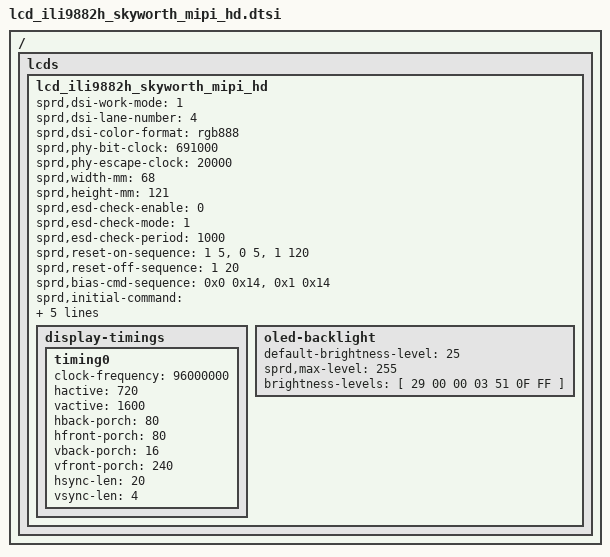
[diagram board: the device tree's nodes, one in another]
/ { lcds {
	lcd_ili9882h_skyworth_mipi_hd: lcd_ili9882h_skyworth_mipi_hd {

		sprd,dsi-work-mode = <1>;
		sprd,dsi-lane-number = <4>;
		sprd,dsi-color-format = "rgb888";

		sprd,phy-bit-clock = <691000>;
		sprd,phy-escape-clock = <20000>;

		sprd,width-mm = <68>;
		sprd,height-mm = <121>;

		sprd,esd-check-enable = <0>;
		sprd,esd-check-mode = <1>;
		sprd,esd-check-period = <1000>;

		sprd,reset-on-sequence = <1 5>, <0 5>, <1 120>;
		sprd,reset-off-sequence = <1 20>;
		sprd,bias-cmd-sequence =  <0x0 0x14>, <0x1 0x14>;

		sprd,initial-command = [
			39 00 00 04 FF 98 82 01
			23 00 00 02 00 41  //42 STV A rise    20201022
			23 00 00 02 01 32  //33 STV A overlap 20201022
			23 00 00 02 02 01
			23 00 00 02 03 00
			23 00 00 02 04 03  //02 STV B rise    20201022
			23 00 00 02 05 30  //31 STV B overlap 20201022
			23 00 00 02 07 00
			23 00 00 02 08 01  //80 CLK A rise    20201022    
			23 00 00 02 09 80  //81 CLK A fall    20201022 
			23 00 00 02 0a 70  //71 CLK A overlap 20201022
			23 00 00 02 0b 00
			23 00 00 02 0c 0E  //01               20201022
			23 00 00 02 0d 0E  //01               20201022
			23 00 00 02 0e 00
			23 00 00 02 0f 00
			23 00 00 02 28 88 //83 STCH1 RISE     20201022
			23 00 00 02 29 88 //STCH1 FALL     
			23 00 00 02 2a 00
			23 00 00 02 2b 00
			23 00 00 02 31 07
			23 00 00 02 32 0c
			23 00 00 02 33 22
			23 00 00 02 34 23 //GOUT_4R_FW
			23 00 00 02 35 07
			23 00 00 02 36 08
			23 00 00 02 37 16
			23 00 00 02 38 14
			23 00 00 02 39 12
			23 00 00 02 3a 10
			23 00 00 02 3b 21
			23 00 00 02 3c 07 //GOUT_12R_FW
			23 00 00 02 3d 07
			23 00 00 02 3e 07
			23 00 00 02 3f 07
			23 00 00 02 40 07
			23 00 00 02 41 07
			23 00 00 02 42 07
			23 00 00 02 43 07
			23 00 00 02 44 07
			23 00 00 02 45 07
			23 00 00 02 46 07                                      
			23 00 00 02 47 07
			23 00 00 02 48 0d
			23 00 00 02 49 22
			23 00 00 02 4a 23 //GOUT_4L_FW
			23 00 00 02 4b 07
			23 00 00 02 4c 09
			23 00 00 02 4d 17
			23 00 00 02 4e 15
			23 00 00 02 4f 13
			23 00 00 02 50 11
			23 00 00 02 51 21
			23 00 00 02 52 07 //GOUT_12L_FW
			23 00 00 02 53 07
			23 00 00 02 54 07
			23 00 00 02 55 07
			23 00 00 02 56 07
			23 00 00 02 57 07
			23 00 00 02 58 07
			23 00 00 02 59 07
			23 00 00 02 5a 07
			23 00 00 02 5b 07
			23 00 00 02 5c 07

			23 00 00 02 61 07
			23 00 00 02 62 0d
			23 00 00 02 63 22
			23 00 00 02 64 23 //GOUT_4R_BW
			23 00 00 02 65 07
			23 00 00 02 66 09
			23 00 00 02 67 11
			23 00 00 02 68 13
			23 00 00 02 69 15
			23 00 00 02 6a 17
			23 00 00 02 6b 21
			23 00 00 02 6c 07 //GOUT_12R_BW
			23 00 00 02 6d 07
			23 00 00 02 6e 07
			23 00 00 02 6f 07
			23 00 00 02 70 07
			23 00 00 02 71 07
			23 00 00 02 72 07
			23 00 00 02 73 07
			23 00 00 02 74 07
			23 00 00 02 75 07
			23 00 00 02 76 07                                        
			23 00 00 02 77 07
			23 00 00 02 78 0c
			23 00 00 02 79 22
			23 00 00 02 7a 23 //GOUT_4L_BW
			23 00 00 02 7b 07
			23 00 00 02 7c 08
			23 00 00 02 7d 10
			23 00 00 02 7e 12
			23 00 00 02 7f 14
			23 00 00 02 80 16
			23 00 00 02 81 21
			23 00 00 02 82 07 //GOUT_12L_BW
			23 00 00 02 83 07
			23 00 00 02 84 07
			23 00 00 02 85 07
			23 00 00 02 86 07
			23 00 00 02 87 07
			23 00 00 02 88 07
			23 00 00 02 89 07
			23 00 00 02 8a 07
			23 00 00 02 8b 07
			23 00 00 02 8c 07
			23 00 00 02 a0 01
			23 00 00 02 a7 00  //LVRA CLK RISE CLW
			23 00 00 02 a8 00  //LVRA CLK RISE CLW
			23 00 00 02 b0 33
			23 00 00 02 ba 06
			23 00 00 02 c0 07
			23 00 00 02 c1 00
			23 00 00 02 c2 00
			23 00 00 02 c3 00
			23 00 00 02 c4 00
			23 00 00 02 ca 44                                
			23 00 00 02 d0 01
			23 00 00 02 d1 22
			23 00 00 02 d3 40
			23 00 00 02 d5 51
			23 00 00 02 d6 20
			23 00 00 02 d7 01
			23 00 00 02 d8 00
			23 00 00 02 dc c2
			23 00 00 02 dd 10
			23 00 00 02 df b6
			23 00 00 02 e0 3E
			23 00 00 02 e2 47 //SRC power off GND
			23 00 00 02 e7 54                                       
			23 00 00 02 e6 22
			23 00 00 02 ee 15
			23 00 00 02 f1 00
			23 00 00 02 f2 00
			23 00 00 02 fa df

			// RTN. Internal VBP, Internal VFP
			39 00 00 04 FF 98 82 02
			23 00 00 02 06 9F     // Internal Line Time (RTN)  9C  20200813
			23 00 00 02 0B A0     // Internal VFP[9]
			23 00 00 02 0C 00     // Internal VFP[8]
			23 00 00 02 0D 1C     // Internal VBP
			23 00 00 02 0E 43     // Internal VFP
			23 00 00 02 F1 1C     // Tcon ESD option
			23 00 00 02 4B 5A     // line_chopper
			23 00 00 02 50 CA     // line_chopper
			23 00 00 02 51 50     // line_chopper
			23 00 00 02 40 4B     // Data_in=7us
			23 00 00 02 4D CE     // Power Saving Off
			23 00 00 02 73 04     // notch tuning
			23 00 00 02 70 32     // notch tuning   
			39 00 00 04 FF 98 82 03
			23 00 00 02 85 40	//DIVIDUAL
			23 00 00 02 87 4D	//01
			23 00 00 02 88 C5
			23 00 00 02 89 E5
			23 00 00 02 8A EF
			23 00 00 02 8B FF
			23 00 00 02 8C D2	//02
			23 00 00 02 8D D6
			23 00 00 02 8E DA
			23 00 00 02 8F DE
			23 00 00 02 90 DF
			23 00 00 02 91 E6
			23 00 00 02 92 E9
			23 00 00 02 93 ED
			23 00 00 02 94 F0
			23 00 00 02 95 FF
			23 00 00 02 96 B5	//03
			23 00 00 02 97 BA
			23 00 00 02 98 BF
			23 00 00 02 99 C3
			23 00 00 02 9A C9
			23 00 00 02 9B CD		
			23 00 00 02 9C D9
			23 00 00 02 9D E6
			23 00 00 02 9E F6		
			23 00 00 02 9F FB


			// Power Setting
			39 00 00 04 FF 98 82 05
			23 00 00 02 A8 62
			23 00 00 02 63 73     // GVDDN = -4.8V
			23 00 00 02 64 73     // GVDDP = 4.8V
			23 00 00 02 68 65     // VGHO = 12V
			23 00 00 02 69 6B     // VGH = 13V
			23 00 00 02 6A A1     // VGLO = -12V
			23 00 00 02 6B 93     // VGL = -13V
			23 00 00 02 00 01     // Panda Enable
			23 00 00 02 46 00     // LVD HVREG option 
			23 00 00 02 45 01     // VGHO/DCHG1/DCHG2 DELAY OPTION Default
			23 00 00 02 17 50     // LVD rise debounce
			23 00 00 02 18 01     // Keep LVD state
			23 00 00 02 85 37      // HW RESET option
			23 00 00 02 86 0F     // FOR PANDA GIP DCHG1/2ON EN

			// Resolution
			39 00 00 04 FF 98 82 06
			23 00 00 02 D9 1F     // 4Lane
			23 00 00 02 C0 40     // NL = 1600
			23 00 00 02 C1 16     // NL = 1600
			23 00 00 02 07 F7     // ABNORMAL RESET OPTION

			//Gamma Register
			39 00 00 04 FF 98 82 08
			39 00 00 1C E0 40 24 9C D5 15 55 45 6A 92 B2 A9 E2 08 29 48 AA 68 91 AD D2 FE F3 1F 58 89 03 EC
			39 00 00 1C E1 40 24 9C D5 15 55 45 6A 92 B2 A9 E2 08 29 48 AA 68 91 AD D2 FE F3 1F 58 89 03 EC

			// OSC Auto Trim Setting
			39 00 00 04 FF 98 82 0B
			23 00 00 02 9A 44
			23 00 00 02 9B FF
			23 00 00 02 9C 04
			23 00 00 02 9D 04
			23 00 00 02 9E 7D
			23 00 00 02 9F 7D
			23 00 00 02 AB E0     // AutoTrimType

			39 00 00 04 FF 98 82 0C
			23 00 00 02 00 1F
			23 00 00 02 01 4E
			23 00 00 02 02 1F
			23 00 00 02 03 4D
			23 00 00 02 04 1E
			23 00 00 02 05 44
			23 00 00 02 06 20
			23 00 00 02 07 58
			23 00 00 02 08 1D
			23 00 00 02 09 3C
			23 00 00 02 0A 1E
			23 00 00 02 0B 48
			23 00 00 02 0C 1F
			23 00 00 02 0D 51
			23 00 00 02 0E 20
			23 00 00 02 0F 56
			23 00 00 02 10 1E
			23 00 00 02 11 49
			23 00 00 02 12 1F
			23 00 00 02 13 52
			23 00 00 02 14 1E
			23 00 00 02 15 43
			23 00 00 02 16 20
			23 00 00 02 17 57
			23 00 00 02 18 1E
			23 00 00 02 19 4A
			23 00 00 02 1A 1E
			23 00 00 02 1B 41
			23 00 00 02 1C 20
			23 00 00 02 1D 59
			23 00 00 02 1E 1E
			23 00 00 02 1F 47
			23 00 00 02 20 1E
			23 00 00 02 21 40
			23 00 00 02 22 1E
			23 00 00 02 23 45
			23 00 00 02 24 1F
			23 00 00 02 25 50
			23 00 00 02 26 1F
			23 00 00 02 27 4F
			23 00 00 02 28 1D
			23 00 00 02 29 3F
			23 00 00 02 2A 1D
			23 00 00 02 2B 3D
			23 00 00 02 2C 1F
			23 00 00 02 2D 53
			23 00 00 02 2E 1E
			23 00 00 02 2F 46
			23 00 00 02 30 1E
			23 00 00 02 31 4C
			23 00 00 02 32 1E
			23 00 00 02 33 42
			23 00 00 02 34 1E
			23 00 00 02 35 4B
			23 00 00 02 36 1F
			23 00 00 02 37 54
			23 00 00 02 38 20
			23 00 00 02 39 5A
			23 00 00 02 3A 1D
			23 00 00 02 3B 3E
			23 00 00 02 3C 1F
			23 00 00 02 3D 55

			39 00 00 04 FF 98 82 0E
			23 00 00 02 00 A3     // LH mode
			23 00 00 02 02 09     // VBP_TPV
			23 00 00 02 07 21     // TPMEnable, 30: Disable
			23 00 00 02 11 50     // TSVD Rise Poisition
			23 00 00 02 13 10     // TSHD Rise Poisition
			23 00 00 02 40 07     // Tp unit
			23 00 00 02 45 0B     // Real Tp term2_unit0  ( >180us ) 
			23 00 00 02 46 59     // Real Tp term2_unit0  ( >180us ) 
			23 00 00 02 49 C8     // Unit line number
			23 00 00 02 4B 1E     // TPM Step: 31
			23 00 00 02 4D 8D     // RTN2_A
			23 00 00 02 C0 01     // Tp term1 Number
			23 00 00 02 C1 80     // Tp term1
			23 00 00 02 D0 34     // Tp term3 Number
			23 00 00 02 D6 8D     // Tp term3_4
			23 00 00 02 D7 8D     // Tp term3_3
			23 00 00 02 D8 8D     // Tp term3_2
			23 00 00 02 D9 8D     // Tp term3_1
			23 00 00 02 DC 44     // Tp 3_3 & 3_4 SRC_OPT
			23 00 00 02 DD 44     // Tp 3_1 & 3_2 SRC_OPT

			//PWM
			39 00 00 04 FF 98 82 06
			23 00 00 02 06 A4

			39 00 00 04 FF 98 82 03
			23 00 00 02 80 04     // 1 frame , 16 step 20201022
			23 00 00 02 81 04     // 1 frame , 16 step 20201022
			23 00 00 02 82 04     // 1 frame , 16 step 20201022
			23 00 00 02 83 E8     //40 PWM=15.6K       20201022 
			23 00 00 02 84 00     //02                 20201022
			23 00 00 02 C6 14     //DEV 8bit&PWM 12bit 20201022

			39 00 00 04 FF 98 82 00
			39 00 00 03 51 00 00
			23 00 00 02 53 2C
			23 00 00 02 55 03
			39 00 00 03 68 04 00  // Set TT:1 frame , 16 step 20201022
			39 00 00 04 FF 98 82 00
			23 00 00 02 11 00
			13 78 00 01 11
			13 14 00 01 29
			23 00 00 02 35 00
			];
		sprd,sleep-in-command = [
			13 32 00 01 28
			13 78 00 01 10
			];
		sprd,sleep-out-command = [
			13 78 00 01 11
			13 64 00 01 29
			];

		display-timings {
			timing0 {
				clock-frequency = <96000000>;
				hactive = <720>;
				vactive = <1600>;
				hback-porch = <80>;
				hfront-porch = <80>;
				vback-porch = <16>;
				vfront-porch = <240>;
				hsync-len = <20>;
				vsync-len = <4>;
			};
		};

oled-backlight{
	default-brightness-level = <25>;
	sprd,max-level = <255>;
	brightness-levels = [
		29 00 00 03 51 0F FF
	];
};
};

};};
